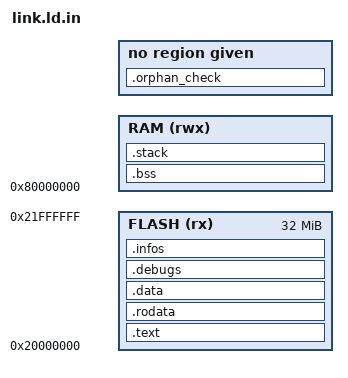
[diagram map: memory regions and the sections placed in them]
/* RISC-V64 BIOS 链接脚本 */

OUTPUT_ARCH(riscv)
/* cause this is bios, _start must locate at 0x20000000 for riscv virt machine */
ENTRY(_start)

MEMORY
{
    /* QEMU virt机器的flash起始地址 */
    FLASH (rx) : ORIGIN = 0x20000000, LENGTH = 32M
    /* size of this memory is revelant to qemu -m param */ 
    RAM (rwx)  : ORIGIN = 0x80000000, LENGTH = @RAM_SIZE@
}

/* *(.text.*): *() -> * match all of the object files */
/* bios.o(.data) -> only .data in bios.o file */

SECTIONS
{
    /* 代码段 - 放在Flash中 */
    .text : {
        *(.text)           /* 主要代码 */
        *(.text.*)
        *(.text.init)      /* 初始化代码 */
    } > FLASH
    
    /* 只读数据段 */
    .rodata : {
        *(.rodata)
        *(.rodata.*)
        *(.string)
    } > FLASH
    
    /* 数据段 */
    .data : {
        *(.data)
        *(.data.*)
    } > FLASH
    
    /* BSS段 - 未初始化数据 */
    .bss : {
        _bss_start = .;
        *(.bss)
        *(.bss.*)
        *(COMMON)
        _bss_end = .;
    } > RAM
    
    /* 栈段 */
    .stack : {
        . = ALIGN(16);
        _mstack_start = .;
        . = . + 2K;
        _mstack_end = .;
    } > RAM
    
    /* 丢弃不需要的段 */
    /DISCARD/ : {
        *(.comment)
        *(.note)
        *(.eh_frame)
    }

    .debugs : {
        *(.debug_*)
    } > FLASH

    .infos : {
        *(.rela*)
        *(.riscv.attributes)
    } > FLASH

    /* check oraph section */
    .orphan_check (NOLOAD) : {
        __orphan_start = .;
        *(*)
        __orphan_end = .;
    }
    ASSERT(__orphan_start == __orphan_end, "存在孤儿段!")
    /* PROVIDE equal to _weak */
    PROVIDE(__orphan_warning = "存在未放置段");
}

/* 定义一些有用的符号 */
_text_start = ADDR(.text);
_text_end = ADDR(.text) + SIZEOF(.text);
_data_start = ADDR(.data);
_data_end = ADDR(.data) + SIZEOF(.data);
